VERSION ""

NS_ :

BS_:

BU_:

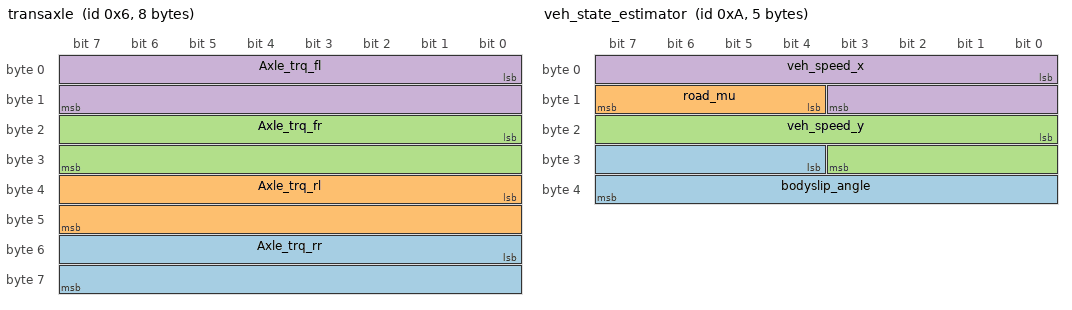
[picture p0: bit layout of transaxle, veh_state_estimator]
BO_ 6 transaxle: 8 Vector__XXX
 SG_ Axle_trq_rr : 48|16@1- (0.061,0) [-1000|1000] "Nm" Vector__XXX
 SG_ Axle_trq_rl : 32|16@1- (0.061,0) [-1000|1000] "Nm" Vector__XXX
 SG_ Axle_trq_fr : 16|16@1- (0.061,0) [-1000|1000] "Nm" Vector__XXX
 SG_ Axle_trq_fl : 0|16@1- (0.061,0) [-1000|1000] "Nm" Vector__XXX

BO_ 10 veh_state_estimator: 5 Vector__XXX
 SG_ bodyslip_angle : 28|12@1- (0.0002,0) [-0.2|0.2] "rad" Vector__XXX
 SG_ road_mu : 12|4@1+ (0.074,0) [0|1.2] "" Vector__XXX
 SG_ veh_speed_y : 16|12@1- (0.0293,0) [-30|30] "m/s" Vector__XXX
 SG_ veh_speed_x : 0|12@1- (0.0293,20) [-10|50] "m/s" Vector__XXX

BO_ 5 engine: 3 Vector__XXX
 SG_ Engine_RPM : 0|12@1+ (2,0) [0|8000] "rpm" Vector__XXX
 SG_ Engine_trq : 12|12@1+ (0.0366,0) [0|150] "Nm" Vector__XXX

BO_ 100 artificial_load_2: 8 Vector__XXX
 SG_ BusLoad_2 : 0|64@1- (1,0) [0|100] "Nm" Vector__XXX

BO_ 0 artifical_load_1: 4 Vector__XXX
 SG_ BusLoad_1 : 0|32@1- (1,0) [0|100] "m" Vector__XXX

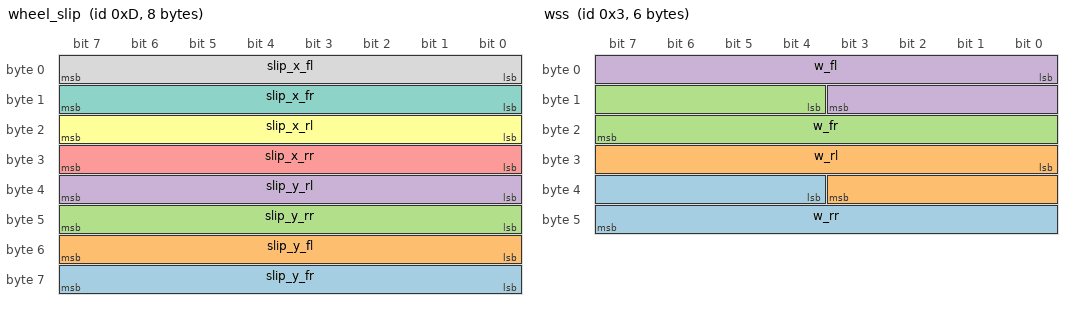
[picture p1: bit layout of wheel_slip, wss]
BO_ 13 wheel_slip: 8 Vector__XXX
 SG_ slip_y_fr : 56|8@1- (0.2344,0) [-0.26|0.26] "rad" Vector__XXX
 SG_ slip_y_fl : 48|8@1- (0.2344,0) [-0.26|0.26] "rad" Vector__XXX
 SG_ slip_y_rr : 40|8@1- (0.2344,0) [-0.26|0.26] "rad" Vector__XXX
 SG_ slip_y_rl : 32|8@1- (0.2344,0) [-0.26|0.26] "" Vector__XXX
 SG_ slip_x_rr : 24|8@1- (0.0157,0) [-1|1] "rad" Vector__XXX
 SG_ slip_x_rl : 16|8@1- (0.0157,0) [-1|1] "" Vector__XXX
 SG_ slip_x_fr : 8|8@1- (0.0157,0) [-1|1] "" Vector__XXX
 SG_ slip_x_fl : 0|8@1- (0.0157,0) [-1|1] "" Vector__XXX

BO_ 50 ECU_1: 4 Vector__XXX
 SG_ ESP_Mz : 0|32@1- (1,0) [-20000|20000] "Nm" Vector__XXX

BO_ 3 wss: 6 Vector__XXX
 SG_ w_rr : 36|12@1+ (0.0366,0) [0|150] "rad/s" Vector__XXX
 SG_ w_rl : 24|12@1+ (0.0366,0) [0|150] "rad/s" Vector__XXX
 SG_ w_fr : 12|12@1+ (0.0366,0) [0|150] "rad/s" Vector__XXX
 SG_ w_fl : 0|12@1+ (0.0366,0) [0|150] "rad/s" Vector__XXX

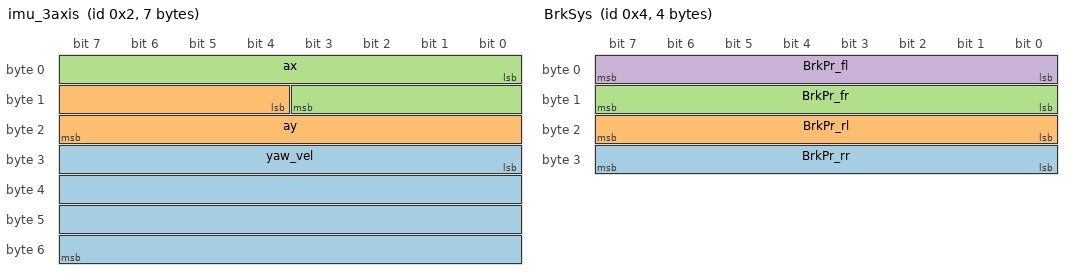
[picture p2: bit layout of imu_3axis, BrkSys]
BO_ 2 imu_3axis: 7 Vector__XXX
 SG_ yaw_vel : 24|32@1- (1,0) [-2|2] "rad/s" Vector__XXX
 SG_ ay : 12|12@1- (0.0015,0) [-1.5|1.5] "g" Vector__XXX
 SG_ ax : 0|12@1- (0.0015,0) [-1.5|1.5] "g" Vector__XXX

BO_ 12 Fy_tyre: 7 Vector__XXX
 SG_ Fy_rr : 36|16@1- (0.244,0) [-4000|4000] "N" Vector__XXX
 SG_ Fy_rl : 24|16@1- (0.244,0) [-4000|4000] "N" Vector__XXX
 SG_ Fy_fr : 12|16@1- (0.244,0) [-4000|4000] "N" Vector__XXX
 SG_ Fy_fl : 0|16@1- (0.244,0) [-4000|4000] "N" Vector__XXX

BO_ 11 Fx_tyre: 7 Vector__XXX
 SG_ Fx_rr : 36|16@1- (0.244,0) [-4000|4000] "N" Vector__XXX
 SG_ Fx_rl : 24|16@1- (0.244,0) [-4000|4000] "N" Vector__XXX
 SG_ Fx_fr : 12|16@1- (0.244,0) [-4000|4000] "N" Vector__XXX
 SG_ Fx_fl : 0|16@1- (0.244,0) [-4000|4000] "N" Vector__XXX

BO_ 4 BrkSys: 4 Vector__XXX
 SG_ BrkPr_rr : 24|8@1+ (1,0) [0|250] "MPa" Vector__XXX
 SG_ BrkPr_rl : 16|8@1+ (1,0) [0|250] "MPa" Vector__XXX
 SG_ BrkPr_fr : 8|8@1+ (1,0) [0|250] "MPa" Vector__XXX
 SG_ BrkPr_fl : 0|8@1+ (1,0) [0|250] "MPa" Vector__XXX

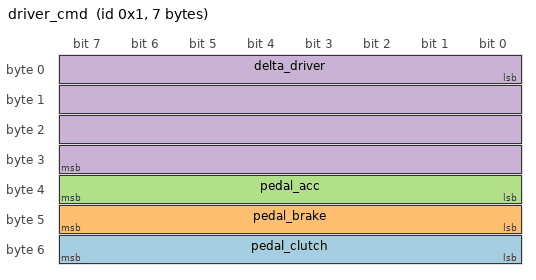
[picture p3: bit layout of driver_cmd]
BO_ 1 driver_cmd: 7 Vector__XXX
 SG_ pedal_clutch : 48|8@1+ (0.0039,0) [0|1] "" Vector__XXX
 SG_ pedal_brake : 40|8@1+ (0.0039,0) [0|1] "" Vector__XXX
 SG_ pedal_acc : 32|8@1+ (0.0039,0) [0|1] "" Vector__XXX
 SG_ delta_driver : 0|32@1- (1,0) [-8|8] "rad" Vector__XXX

BA_DEF_  "BusType" STRING ;
BA_DEF_DEF_  "BusType" "CAN";
SIG_VALTYPE_ 100 BusLoad_2 : 2;
SIG_VALTYPE_ 0 BusLoad_1 : 1;
SIG_VALTYPE_ 50 ESP_Mz : 1;
SIG_VALTYPE_ 2 yaw_vel : 1;
SIG_VALTYPE_ 1 delta_driver : 1;
